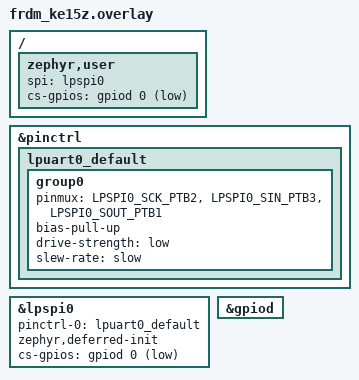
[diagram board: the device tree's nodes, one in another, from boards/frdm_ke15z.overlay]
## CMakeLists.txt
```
# SPDX-License-Identifier: Apache-2.0

cmake_minimum_required(VERSION 3.20.0)
find_package(Zephyr REQUIRED HINTS $ENV{ZEPHYR_BASE})
project(deinit)

target_sources(app PRIVATE src/main.c)
```

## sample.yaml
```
sample:
  name: Device deinit
tests:
  sample.application_development.deinit:
    platform_allow:
      - nrf5340dk/nrf5340/cpuapp
    harness: console
    harness_config:
      type: one_line
      regex:
        - "sample complete"
```

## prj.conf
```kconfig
CONFIG_SPI=y
CONFIG_GPIO=y
```

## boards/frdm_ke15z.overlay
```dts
/*
 * Copyright 2025 Nordic Semiconductor ASA
 *
 * SPDX-License-Identifier: Apache-2.0
 */

&pinctrl {
	lpuart0_default: lpuart0_default {
		group0 {
			pinmux = <LPSPI0_SCK_PTB2>,
				 <LPSPI0_SIN_PTB3>,
				 <LPSPI0_SOUT_PTB1>;
			bias-pull-up;
			drive-strength = "low";
			slew-rate = "slow";
		};
	};
};

&lpspi0 {
	pinctrl-0 = <&lpuart0_default>;
	pinctrl-names = "default";
	status = "okay";
	zephyr,deferred-init;
	cs-gpios = <&gpiod 0 GPIO_ACTIVE_LOW>;
};

&gpiod {
	status = "okay";
};

/ {
	zephyr,user {
		spi = <&lpspi0>;
		cs-gpios = <&gpiod 0 GPIO_ACTIVE_LOW>;
	};
};
```

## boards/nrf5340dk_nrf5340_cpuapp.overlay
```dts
/*
 * Copyright 2025 Nordic Semiconductor ASA
 *
 * SPDX-License-Identifier: Apache-2.0
 */

&spi4 {
	status = "okay";
	zephyr,deferred-init;
	cs-gpios = <&gpio0 30 GPIO_ACTIVE_LOW>;
};

/ {
	zephyr,user {
		spi = <&spi4>;
		cs-gpios = <&gpio0 30 GPIO_ACTIVE_LOW>;
	};
};
```

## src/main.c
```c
/*
 * Copyright 2025 Nordic Semiconductor ASA
 *
 * SPDX-License-Identifier: Apache-2.0
 */

#include <zephyr/kernel.h>
#include <zephyr/device.h>
#include <zephyr/drivers/spi.h>
#include <zephyr/drivers/gpio.h>

#define SPI_DEV_NODE DT_PROP(DT_PATH(zephyr_user), spi)

static const struct device *const spi_dev = DEVICE_DT_GET(SPI_DEV_NODE);
static const struct gpio_dt_spec cs_pin = GPIO_DT_SPEC_GET(DT_PATH(zephyr_user), cs_gpios);

static uint8_t tx_buf[8];

static const struct spi_buf tx_buf_pool[1] = {
	{
		.buf = tx_buf,
		.len = sizeof(tx_buf),
	},
};

static const struct spi_buf_set spi_tx_buf = {
	.buffers = tx_buf_pool,
	.count = ARRAY_SIZE(tx_buf_pool),
};

static const struct spi_config config = {
	.frequency = DT_PROP_OR(SPI_DEV_NODE, max_frequency, 1000000),
	.operation = SPI_OP_MODE_MASTER | SPI_HOLD_ON_CS | SPI_WORD_SET(8),
	.slave = 0,
	.cs = {
		.gpio = GPIO_DT_SPEC_GET_OR(SPI_DEV_NODE, cs_gpios, {0}),
		.delay = 0,
	},
};

static int control_cs_pin_with_gpio(void)
{
	int ret;

	ret = gpio_pin_configure_dt(&cs_pin, GPIO_OUTPUT_ACTIVE);
	if (ret) {
		printk("failed to configure CS pin\n");
		return 0;
	}

	k_msleep(1000);

	ret = gpio_pin_configure_dt(&cs_pin, GPIO_INPUT);
	if (ret) {
		printk("failed to configure CS pin\n");
		return 0;
	}

	k_msleep(1000);
	return 0;
}

static int control_cs_pin_with_spi(void)
{
	int ret;

	/*
	 * Perform SPI transaction and keep CS pin asserted after
	 * after transaction (see config.operation).
	 */
	ret = spi_transceive(spi_dev, &config, &spi_tx_buf, NULL);
	if (ret) {
		printk("failed to perform SPI transaction (ret %d)\n", ret);
		return 0;
	}

	k_msleep(1000);

	/* Release SPI device and thus CS pin shall be deasserted */
	ret = spi_release(spi_dev, &config);
	if (ret) {
		printk("failed to release SPI device (ret %d)\n", ret);
		return 0;
	}

	k_msleep(1000);
	return 0;
}

int main(void)
{
	int ret;

	/*
	 * As we have specified deferred init for the SPI device in the devicetree, the driver
	 * will not be initialized at this stage. We should have full control of the CS GPIO,
	 * let's test that.
	 */
	ret = control_cs_pin_with_gpio();
	if (ret) {
		printk("failed to control CS pin with GPIO device driver (ret %d)\n", ret);
		return 0;
	}

	/*
	 * Now lets initialize the SPI device driver.
	 */
	ret = device_init(spi_dev);
	if (ret) {
		printk("failed to init SPI device driver (ret %d)\n", ret);
		return 0;
	}

	/*
	 * To control the CS pin in "human speed", lets perform a mock
	 * transaction, holding the CS pin until we release the SPI device.
	 */
	ret = control_cs_pin_with_spi();
	if (ret) {
		printk("failed to control CS pin with SPI device driver (ret %d)\n", ret);
		return 0;
	}

	/*
	 * Lets deinit the SPI device driver an manually control the
	 * CS pin again.
	 */
	ret = device_deinit(spi_dev);
	if (ret) {
		printk("failed to deinit SPI device driver (ret %d)\n", ret);
		return 0;
	}

	ret = control_cs_pin_with_gpio();
	if (ret) {
		printk("failed to control CS pin with GPIO device driver (ret %d)\n", ret);
		return 0;
	}

	/*
	 * Lastly, lets check if we can bring back the SPI device driver.
	 */
	ret = device_init(spi_dev);
	if (ret) {
		printk("failed to init SPI device driver (ret %d)\n", ret);
		return 0;
	}

	/* One final blink */
	ret = control_cs_pin_with_spi();
	if (ret) {
		printk("failed to control CS pin with SPI device driver (ret %d)\n", ret);
		return 0;
	}

	printk("sample complete\n");
	return 0;
}
```
